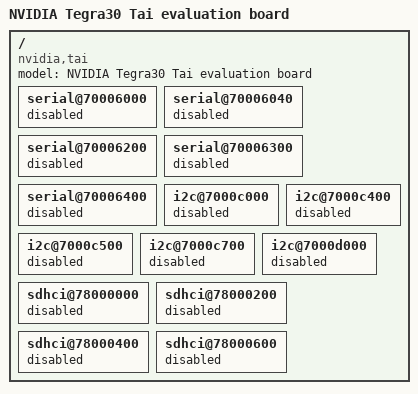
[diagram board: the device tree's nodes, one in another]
/dts-v1/;

/include/ "tegra30.dtsi"

/ {
	model = "NVIDIA Tegra30 Tai evaluation board";
	compatible = "nvidia,tai", "nvidia,tegra30";

	serial@70006000 {
		status = "disable";
	};

	serial@70006040 {
		status = "disable";
	};

	serial@70006200 {
		status = "disable";
	};

	serial@70006300 {
		status = "disable";
	};

	serial@70006400 {
		status = "disable";
	};

	i2c@7000c000 {
		status = "disable";
	};

	i2c@7000c400 {
		status = "disable";
	};

	i2c@7000c500 {
		status = "disable";
	};

	i2c@7000c700 {
		status = "disable";
	};

	i2c@7000d000 {
		status = "disable";
	};

	sdhci@78000000 {
		status = "disable";
	};

	sdhci@78000200 {
		status = "disable";
	};

	sdhci@78000400 {
		status = "disable";
	};

	sdhci@78000600 {
		status = "disable";
	};

};
